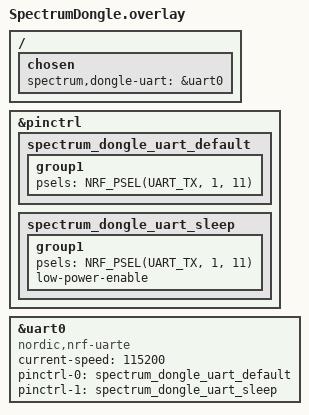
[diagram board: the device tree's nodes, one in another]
#include <zephyr/dt-bindings/pinctrl/nrf-pinctrl.h>

/ {
    chosen {
        spectrum,dongle-uart = &uart0;
    };
};

&pinctrl {
    spectrum_dongle_uart_default: spectrum_dongle_uart_default {
        group1 {
            /* XIAO nRF52840 D6 */
            psels = <NRF_PSEL(UART_TX, 1, 11)>;
        };
    };

    spectrum_dongle_uart_sleep: spectrum_dongle_uart_sleep {
        group1 {
            psels = <NRF_PSEL(UART_TX, 1, 11)>;
            low-power-enable;
        };
    };
};

&uart0 {
    compatible = "nordic,nrf-uarte";
    status = "okay";
    current-speed = <115200>;
    pinctrl-0 = <&spectrum_dongle_uart_default>;
    pinctrl-1 = <&spectrum_dongle_uart_sleep>;
    pinctrl-names = "default", "sleep";
};

